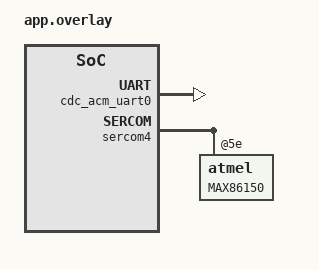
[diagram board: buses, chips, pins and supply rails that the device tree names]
/ {
    chosen {
        zephyr,console = &cdc_acm_uart0;
        
    };
};

&zephyr_udc0 {
    cdc_acm_uart0: cdc_acm_uart0 {
    	compatible = "zephyr,cdc-acm-uart";
        label = "CDC_ACM_0";
    };
};

&sercom4 {
    max86150: max86150@5e {
        compatible = "atmel";
        status = "okay";
        reg = <0x5e>;
        label="MAX86150";
    };
};
